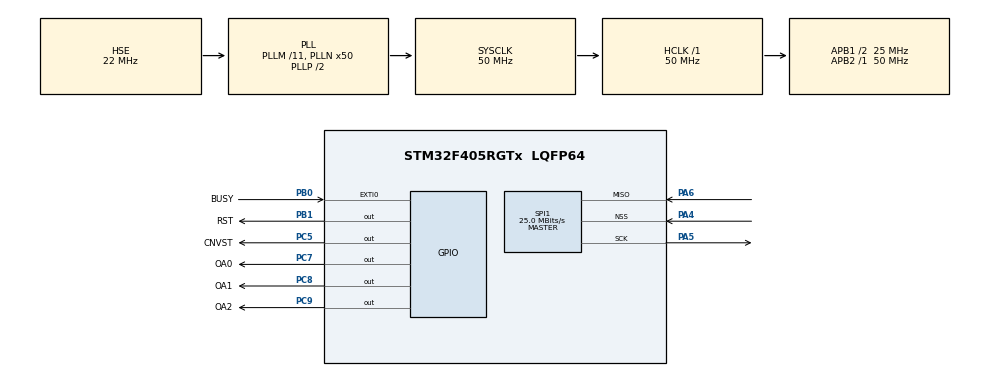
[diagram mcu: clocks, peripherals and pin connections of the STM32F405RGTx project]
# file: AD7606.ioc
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Mcu.Family=STM32F4
Mcu.Name=STM32F405RGTx
Mcu.Package=LQFP64
NVIC.PriorityGroup=NVIC_PRIORITYGROUP_4
PA13.Mode=Serial_Wire
PA13.Signal=SYS_JTMS-SWDIO
PA14.Mode=Serial_Wire
PA14.Signal=SYS_JTCK-SWCLK
PA4.Mode=NSS_Signal_Hard_Input
PA4.Signal=SPI1_NSS
PA5.Mode=RX_Only_Simplex_Unidirect_Master
PA5.Signal=SPI1_SCK
PA6.Mode=RX_Only_Simplex_Unidirect_Master
PA6.Signal=SPI1_MISO
PB0.GPIO_Label=BUSY
PB0.Signal=GPXTI0
PB1.GPIO_Label=RST
PB1.PinState=GPIO_PIN_SET
PB1.Signal=GPIO_Output
PC5.GPIO_Label=CNVST
PC5.Signal=GPIO_Output
PC7.GPIO_Label=OA0
PC7.GPIO_PuPd=GPIO_PULLDOWN
PC7.PinState=GPIO_PIN_RESET
PC7.Signal=GPIO_Output
PC8.GPIO_Label=OA1
PC8.GPIO_PuPd=GPIO_PULLUP
PC8.PinState=GPIO_PIN_RESET
PC8.Signal=GPIO_Output
PC9.GPIO_Label=OA2
PC9.GPIO_PuPd=GPIO_PULLUP
PC9.PinState=GPIO_PIN_RESET
PC9.Signal=GPIO_Output
PH0-OSC_IN.Mode=HSE-External-Oscillator
PH0-OSC_IN.Signal=RCC_OSC_IN
PH1-OSC_OUT.Mode=HSE-External-Oscillator
PH1-OSC_OUT.Signal=RCC_OSC_OUT
ProjectManager.HeapSize=0x200
ProjectManager.StackSize=0x400
ProjectManager.TargetToolchain=STM32CubeIDE
RCC.48MHZClocksFreq_Value=25000000
RCC.AHBFreq_Value=50000000
RCC.APB1CLKDivider=RCC_HCLK_DIV2
RCC.APB1Freq_Value=25000000
RCC.APB1TimFreq_Value=50000000
RCC.APB2Freq_Value=50000000
RCC.APB2TimFreq_Value=50000000
RCC.CortexFreq_Value=50000000
RCC.HCLKFreq_Value=50000000
RCC.HSE_VALUE=22000000
RCC.HSI_VALUE=16000000
RCC.LSE_VALUE=32768
RCC.PLLM=11
RCC.PLLN=50
RCC.PLLSourceVirtual=RCC_PLLSOURCE_HSE
RCC.SYSCLKFreq_VALUE=50000000
RCC.SYSCLKSource=RCC_SYSCLKSOURCE_PLLCLK
RCC.VCOOutputFreq_Value=100000000
SPI1.BaudRatePrescaler=SPI_BAUDRATEPRESCALER_2
SPI1.CalculateBaudRate=25.0 MBits/s
SPI1.Direction=SPI_DIRECTION_2LINES_RXONLY
SPI1.Mode=SPI_MODE_MASTER
SPI1.VirtualNSS=VM_NSSHARD
SPI1.VirtualType=VM_MASTER
board=custom

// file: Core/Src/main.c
/* USER CODE BEGIN Header */
/**
  ********************************----------------------------------------------
  * @file           : main.c
  * @brief          : Main program body
  ********************************----------------------------------------------
  * @attention
  *
  * Copyright (c) 2026 STMicroelectronics.
  * All rights reserved.
  *
  * This software is licensed under terms that can be found in the LICENSE file
  * in the root directory of this software component.
  * If no LICENSE file comes with this software, it is provided AS-IS.
  *
  ********************************----------------------------------------------
  */
/* USER CODE END Header */
#include "main.h"

SPI_HandleTypeDef hspi1;

/* USER CODE BEGIN PV */
int16_t adc_data[8];
float adc_voltages[8];
/* USER CODE END PV */

void SystemClock_Config(void);
static void MX_GPIO_Init(void);
static void MX_SPI1_Init(void);
/* USER CODE BEGIN PFP */
void AD7606_Reset(void);
void AD7606_Init(void);
HAL_StatusTypeDef AD7606_Read_Channels(int16_t *output_buffer);
/* USER CODE END PFP */

int main(void)
{

  /* MCU Configuration--------------------------------------------------------*/

  /* Reset of all peripherals, Initializes the Flash interface and the Systick. */
  HAL_Init();

  /* Configure the system clock */
  SystemClock_Config();

  /* Initialize all configured peripherals */
  MX_GPIO_Init();
  MX_SPI1_Init();

  /* USER CODE BEGIN 2 */
  AD7606_Init();
  /* USER CODE END 2 */

  /* Infinite loop */
  /* USER CODE BEGIN WHILE */
  while (1)
  {
    if (AD7606_Read_Channels(adc_data) == HAL_OK)
    {
      for (int i = 0; i < 8; i++)
      {
        // Convert raw 16-bit signed ADC counts to voltage (Assuming ±10V range: 32768 = 10.0V)
        // Change to 5.0f if your hardware configuration uses a ±5V range.
        adc_voltages[i] = ((float)adc_data[i] / 32768.0f) * 10.0f;
      }
    }

    // Optional delay or trigger rate control
    // HAL_Delay(10);
    /* USER CODE END WHILE */

  }
}

void SystemClock_Config(void)
{
  RCC_OscInitTypeDef RCC_OscInitStruct = {0};
  RCC_ClkInitTypeDef RCC_ClkInitStruct = {0};

  /** Configure the main internal regulator output voltage
  */
  __HAL_RCC_PWR_CLK_ENABLE();
  __HAL_PWR_VOLTAGESCALING_CONFIG(PWR_REGULATOR_VOLTAGE_SCALE1);

  /** Initializes the RCC Oscillators according to the specified parameters
  * in the RCC_OscInitTypeDef structure.
  */
  RCC_OscInitStruct.OscillatorType = RCC_OSCILLATORTYPE_HSE;
  RCC_OscInitStruct.HSEState = RCC_HSE_ON;
  RCC_OscInitStruct.PLL.PLLState = RCC_PLL_ON;
  RCC_OscInitStruct.PLL.PLLSource = RCC_PLLSOURCE_HSE;
  RCC_OscInitStruct.PLL.PLLM = 11;
  RCC_OscInitStruct.PLL.PLLN = 50;
  RCC_OscInitStruct.PLL.PLLP = RCC_PLLP_DIV2;
  RCC_OscInitStruct.PLL.PLLQ = 4;
  if (HAL_RCC_OscConfig(&RCC_OscInitStruct) != HAL_OK)
  {
    Error_Handler();
  }

  /** Initializes the CPU, AHB and APB buses clocks
  */
  RCC_ClkInitStruct.ClockType = RCC_CLOCKTYPE_HCLK|RCC_CLOCKTYPE_SYSCLK
                              |RCC_CLOCKTYPE_PCLK1|RCC_CLOCKTYPE_PCLK2;
  RCC_ClkInitStruct.SYSCLKSource = RCC_SYSCLKSOURCE_PLLCLK;
  RCC_ClkInitStruct.AHBCLKDivider = RCC_SYSCLK_DIV1;
  RCC_ClkInitStruct.APB1CLKDivider = RCC_HCLK_DIV2;
  RCC_ClkInitStruct.APB2CLKDivider = RCC_HCLK_DIV1;

  if (HAL_RCC_ClockConfig(&RCC_ClkInitStruct, FLASH_LATENCY_1) != HAL_OK)
  {
    Error_Handler();
  }
}

static void MX_SPI1_Init(void)
{

  /* SPI1 parameter configuration*/
  hspi1.Instance = SPI1;
  hspi1.Init.Mode = SPI_MODE_MASTER;
  hspi1.Init.Direction = SPI_DIRECTION_2LINES_RXONLY;
  hspi1.Init.DataSize = SPI_DATASIZE_8BIT;
  hspi1.Init.CLKPolarity = SPI_POLARITY_LOW;
  hspi1.Init.CLKPhase = SPI_PHASE_1EDGE;
  hspi1.Init.NSS = SPI_NSS_SOFT;
  hspi1.Init.BaudRatePrescaler = SPI_BAUDRATEPRESCALER_2;
  hspi1.Init.FirstBit = SPI_FIRSTBIT_MSB;
  hspi1.Init.TIMode = SPI_TIMODE_DISABLE;
  hspi1.Init.CRCCalculation = SPI_CRCCALCULATION_DISABLE;
  hspi1.Init.CRCPolynomial = 10;

  if (HAL_SPI_Init(&hspi1) != HAL_OK)
  {
    Error_Handler();
  }
}

static void MX_GPIO_Init(void)
{
  GPIO_InitTypeDef GPIO_InitStruct = {0};

  /* GPIO Ports Clock Enable */
  __HAL_RCC_GPIOH_CLK_ENABLE();
  __HAL_RCC_GPIOA_CLK_ENABLE();
  __HAL_RCC_GPIOC_CLK_ENABLE();
  __HAL_RCC_GPIOB_CLK_ENABLE();

  /*Configure GPIO pin Output Level */
  HAL_GPIO_WritePin(GPIOC, CNVST_Pin|OA0_Pin|OA1_Pin|OA2_Pin, GPIO_PIN_RESET);

  /*Configure GPIO pin Output Level */
  HAL_GPIO_WritePin(RST_GPIO_Port, RST_Pin, GPIO_PIN_SET);

  /*Configure GPIO pin Output Level for CS */
  HAL_GPIO_WritePin(ADC_CS_GPIO_Port, ADC_CS_Pin, GPIO_PIN_SET);

  /*Configure GPIO pin : CNVST_Pin */
  GPIO_InitStruct.Pin = CNVST_Pin;
  GPIO_InitStruct.Mode = GPIO_MODE_OUTPUT_PP;
  GPIO_InitStruct.Pull = GPIO_NOPULL;
  GPIO_InitStruct.Speed = GPIO_SPEED_FREQ_LOW;
  HAL_GPIO_Init(CNVST_GPIO_Port, &GPIO_InitStruct);

  /*Configure GPIO pin : BUSY_Pin */
  GPIO_InitStruct.Pin = BUSY_Pin;
  GPIO_InitStruct.Mode = GPIO_MODE_IT_RISING;
  GPIO_InitStruct.Pull = GPIO_NOPULL;
  HAL_GPIO_Init(BUSY_GPIO_Port, &GPIO_InitStruct);

  /*Configure GPIO pin : RST_Pin */
  GPIO_InitStruct.Pin = RST_Pin;
  GPIO_InitStruct.Mode = GPIO_MODE_OUTPUT_PP;
  GPIO_InitStruct.Pull = GPIO_NOPULL;
  GPIO_InitStruct.Speed = GPIO_SPEED_FREQ_LOW;
  HAL_GPIO_Init(RST_GPIO_Port, &GPIO_InitStruct);

  /*Configure GPIO pin : ADC_CS_Pin (FIXED: Added missing CS initialization) */
  GPIO_InitStruct.Pin = ADC_CS_Pin;
  GPIO_InitStruct.Mode = GPIO_MODE_OUTPUT_PP;
  GPIO_InitStruct.Pull = GPIO_NOPULL;
  GPIO_InitStruct.Speed = GPIO_SPEED_FREQ_HIGH;
  HAL_GPIO_Init(ADC_CS_GPIO_Port, &GPIO_InitStruct);

  /*Configure GPIO pin : OA0_Pin */
  GPIO_InitStruct.Pin = OA0_Pin;
  GPIO_InitStruct.Mode = GPIO_MODE_OUTPUT_PP;
  GPIO_InitStruct.Pull = GPIO_PULLDOWN;
  GPIO_InitStruct.Speed = GPIO_SPEED_FREQ_LOW;
  HAL_GPIO_Init(OA0_GPIO_Port, &GPIO_InitStruct);

  /*Configure GPIO pins : OA1_Pin OA2_Pin */
  GPIO_InitStruct.Pin = OA1_Pin|OA2_Pin;
  GPIO_InitStruct.Mode = GPIO_MODE_OUTPUT_PP;
  GPIO_InitStruct.Pull = GPIO_PULLUP;
  GPIO_InitStruct.Speed = GPIO_SPEED_FREQ_LOW;
  HAL_GPIO_Init(GPIOC, &GPIO_InitStruct);

}

/* USER CODE BEGIN 4 */
void AD7606_Reset(void)
{
    HAL_GPIO_WritePin(CNVST_GPIO_Port, CNVST_Pin, GPIO_PIN_RESET);
    HAL_Delay(1);

    HAL_GPIO_WritePin(RST_GPIO_Port, RST_Pin, GPIO_PIN_SET);
    HAL_Delay(1);

    HAL_GPIO_WritePin(RST_GPIO_Port, RST_Pin, GPIO_PIN_RESET);
    HAL_Delay(1);
}

void AD7606_Init(void)
{
    AD7606_Reset();

    // Set oversampling configuration (e.g., 0, 1, 1 for x64 oversampling)
    HAL_GPIO_WritePin(OA0_GPIO_Port, OA0_Pin, GPIO_PIN_RESET);
    HAL_GPIO_WritePin(OA1_GPIO_Port, OA1_Pin, GPIO_PIN_SET);
    HAL_GPIO_WritePin(OA2_GPIO_Port, OA2_Pin, GPIO_PIN_SET);

    while(HAL_GPIO_ReadPin(BUSY_GPIO_Port, BUSY_Pin) == GPIO_PIN_SET);
}

HAL_StatusTypeDef AD7606_Read_Channels(int16_t *output_buffer)
{
    uint8_t spi_raw_data[16];
    uint32_t start_tick;

    if (output_buffer == NULL)
    {
        return HAL_ERROR;
    }

    start_tick = HAL_GetTick();
    while (HAL_GPIO_ReadPin(BUSY_GPIO_Port, BUSY_Pin) == GPIO_PIN_SET)
    {
        if ((HAL_GetTick() - start_tick) > 10U)
        {
            return HAL_TIMEOUT;
        }
    }

    // Start conversion via CONVST rising edge
    HAL_GPIO_WritePin(CNVST_GPIO_Port, CNVST_Pin, GPIO_PIN_SET);
    __NOP(); __NOP(); __NOP();

    HAL_GPIO_WritePin(CNVST_GPIO_Port, CNVST_Pin, GPIO_PIN_RESET);

    start_tick = HAL_GetTick();
    while (HAL_GPIO_ReadPin(BUSY_GPIO_Port, BUSY_Pin) == GPIO_PIN_RESET)
    {
        if ((HAL_GetTick() - start_tick) > 10U)
        {
            return HAL_TIMEOUT;
        }
    }

    start_tick = HAL_GetTick();
    while (HAL_GPIO_ReadPin(BUSY_GPIO_Port, BUSY_Pin) == GPIO_PIN_SET)
    {
        if ((HAL_GetTick() - start_tick) > 10U)
        {
            return HAL_TIMEOUT;
        }
    }

    // Read 8 channels (16 bytes) via SPI
    HAL_GPIO_WritePin(ADC_CS_GPIO_Port, ADC_CS_Pin, GPIO_PIN_RESET);

    HAL_StatusTypeDef status = HAL_SPI_Receive(&hspi1, spi_raw_data, sizeof(spi_raw_data), 10U);

    HAL_GPIO_WritePin(ADC_CS_GPIO_Port, ADC_CS_Pin, GPIO_PIN_SET);

    if (status != HAL_OK)
    {
        return status;
    }

    // Decode big-endian, signed 16-bit values
    for (int i = 0; i < 8; i++)
    {
        uint16_t raw = ((uint16_t)spi_raw_data[2 * i] << 8) | (uint16_t)spi_raw_data[2 * i + 1];
        output_buffer[i] = (int16_t)raw;
    }

    return HAL_OK;
}
/* USER CODE END 4 */

void Error_Handler(void)
{
  __disable_irq();
  while (1)
  {
  }
}
